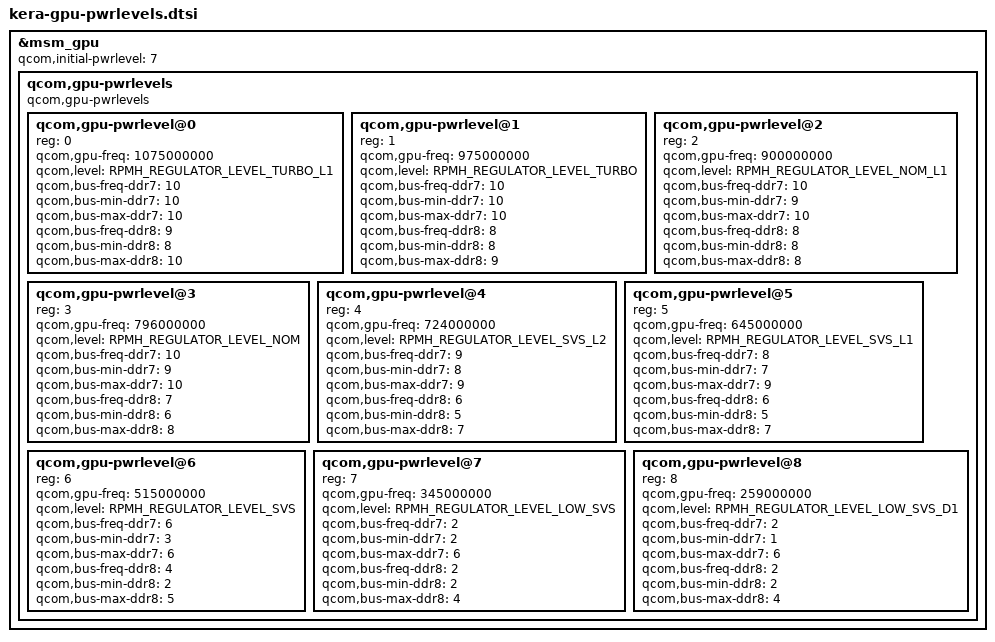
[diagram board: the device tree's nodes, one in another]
// SPDX-License-Identifier: BSD-3-Clause
/*
 * Copyright (c) 2024 Qualcomm Innovation Center, Inc. All rights reserved.
 */

&msm_gpu {
	qcom,initial-pwrlevel = <7>;

	/* Power levels */
	qcom,gpu-pwrlevels {
		compatible="qcom,gpu-pwrlevels";

		#address-cells = <1>;
		#size-cells = <0>;

		/* Turbo_L1 */
		qcom,gpu-pwrlevel@0 {
			reg = <0>;
			qcom,gpu-freq = <1075000000>;
			qcom,level = <RPMH_REGULATOR_LEVEL_TURBO_L1>;

			qcom,bus-freq-ddr7 = <10>;
			qcom,bus-min-ddr7 = <10>;
			qcom,bus-max-ddr7 = <10>;

			qcom,bus-freq-ddr8 = <9>;
			qcom,bus-min-ddr8 = <8>;
			qcom,bus-max-ddr8 = <10>;
		};

		/* Turbo */
		qcom,gpu-pwrlevel@1 {
			reg = <1>;
			qcom,gpu-freq = <975000000>;
			qcom,level = <RPMH_REGULATOR_LEVEL_TURBO>;

			qcom,bus-freq-ddr7 = <10>;
			qcom,bus-min-ddr7 = <10>;
			qcom,bus-max-ddr7 = <10>;

			qcom,bus-freq-ddr8 = <8>;
			qcom,bus-min-ddr8 = <8>;
			qcom,bus-max-ddr8 = <9>;
		};

		/* Nom_L1 */
		qcom,gpu-pwrlevel@2 {
			reg = <2>;
			qcom,gpu-freq = <900000000>;
			qcom,level = <RPMH_REGULATOR_LEVEL_NOM_L1>;

			qcom,bus-freq-ddr7 = <10>;
			qcom,bus-min-ddr7 = <9>;
			qcom,bus-max-ddr7 = <10>;

			qcom,bus-freq-ddr8 = <8>;
			qcom,bus-min-ddr8 = <8>;
			qcom,bus-max-ddr8 = <8>;
		};

		/* Nom */
		qcom,gpu-pwrlevel@3 {
			reg = <3>;
			qcom,gpu-freq = <796000000>;
			qcom,level = <RPMH_REGULATOR_LEVEL_NOM>;

			qcom,bus-freq-ddr7 = <10>;
			qcom,bus-min-ddr7 = <9>;
			qcom,bus-max-ddr7 = <10>;

			qcom,bus-freq-ddr8 = <7>;
			qcom,bus-min-ddr8 = <6>;
			qcom,bus-max-ddr8 = <8>;
		};

		/* SVS_L2 */
		qcom,gpu-pwrlevel@4 {
			reg = <4>;
			qcom,gpu-freq = <724000000>;
			qcom,level = <RPMH_REGULATOR_LEVEL_SVS_L2>;

			qcom,bus-freq-ddr7 = <9>;
			qcom,bus-min-ddr7 = <8>;
			qcom,bus-max-ddr7 = <9>;

			qcom,bus-freq-ddr8 = <6>;
			qcom,bus-min-ddr8 = <5>;
			qcom,bus-max-ddr8 = <7>;
		};

		/* SVS_L1 */
		qcom,gpu-pwrlevel@5 {
			reg = <5>;
			qcom,gpu-freq = <645000000>;
			qcom,level = <RPMH_REGULATOR_LEVEL_SVS_L1>;

			qcom,bus-freq-ddr7 = <8>;
			qcom,bus-min-ddr7 = <7>;
			qcom,bus-max-ddr7 = <9>;

			qcom,bus-freq-ddr8 = <6>;
			qcom,bus-min-ddr8 = <5>;
			qcom,bus-max-ddr8 = <7>;
		};

		/* SVS */
		qcom,gpu-pwrlevel@6 {
			reg = <6>;
			qcom,gpu-freq = <515000000>;
			qcom,level = <RPMH_REGULATOR_LEVEL_SVS>;

			qcom,bus-freq-ddr7 = <6>;
			qcom,bus-min-ddr7 = <3>;
			qcom,bus-max-ddr7 = <6>;

			qcom,bus-freq-ddr8 = <4>;
			qcom,bus-min-ddr8 = <2>;
			qcom,bus-max-ddr8 = <5>;
		};

		/* Low_SVS */
		qcom,gpu-pwrlevel@7 {
			reg = <7>;
			qcom,gpu-freq = <345000000>;
			qcom,level = <RPMH_REGULATOR_LEVEL_LOW_SVS>;

			qcom,bus-freq-ddr7 = <2>;
			qcom,bus-min-ddr7 = <2>;
			qcom,bus-max-ddr7 = <6>;

			qcom,bus-freq-ddr8 = <2>;
			qcom,bus-min-ddr8 = <2>;
			qcom,bus-max-ddr8 = <4>;
		};

		/* Low_SVS_D1 */
		qcom,gpu-pwrlevel@8 {
			reg = <8>;
			qcom,gpu-freq = <259000000>;
			qcom,level = <RPMH_REGULATOR_LEVEL_LOW_SVS_D1>;

			qcom,bus-freq-ddr7 = <2>;
			qcom,bus-min-ddr7 = <1>;
			qcom,bus-max-ddr7 = <6>;

			qcom,bus-freq-ddr8 = <2>;
			qcom,bus-min-ddr8 = <2>;
			qcom,bus-max-ddr8 = <4>;
		};
	};
};
